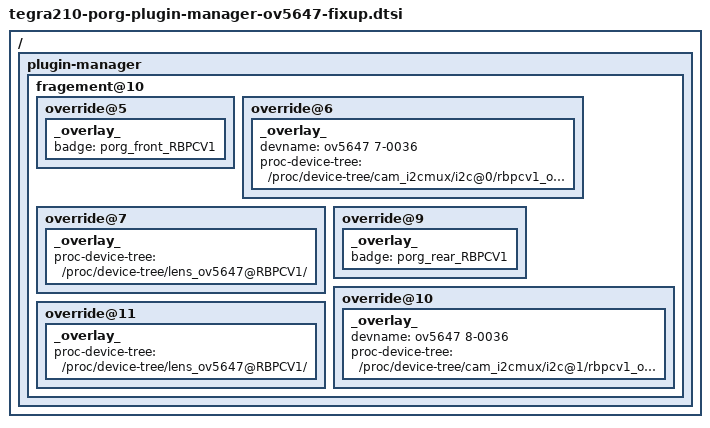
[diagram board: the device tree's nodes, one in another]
/*
 * tegra210-porg-plugin-manager-ov5647-fixup.dtsi
 *
 * The stock porg plugin-manager fragment for B01 modules (ids >= 3448-xxxx-300,
 * "fragement@10" in tegra210-porg-plugin-manager.dtsi) enables the dual camera
 * nodes by label at boot and, in doing so, rewrites the tegra-camera-platform
 * module entries with IMX219 names. Override just those properties so
 * nvargus-daemon looks for the OV5647 v4l2 subdevices instead.
 *
 * This file MUST be included after tegra210-porg-plugin-manager.dtsi
 * (later definitions win in dtc), which is why it is not part of the camera
 * dtsi itself. Node names below match NVIDIA's file exactly, including the
 * "fragement" spelling.
 */

/ {
	plugin-manager {
		fragement@10 {
			override@5 {
				_overlay_ {
					badge = "porg_front_RBPCV1";
				};
			};
			override@6 {
				_overlay_ {
					devname = "ov5647 7-0036";
					proc-device-tree = "/proc/device-tree/cam_i2cmux/i2c@0/rbpcv1_ov5647_a@36";
				};
			};
			override@7 {
				_overlay_ {
					proc-device-tree = "/proc/device-tree/lens_ov5647@RBPCV1/";
				};
			};
			override@9 {
				_overlay_ {
					badge = "porg_rear_RBPCV1";
				};
			};
			override@10 {
				_overlay_ {
					devname = "ov5647 8-0036";
					proc-device-tree = "/proc/device-tree/cam_i2cmux/i2c@1/rbpcv1_ov5647_e@36";
				};
			};
			override@11 {
				_overlay_ {
					proc-device-tree = "/proc/device-tree/lens_ov5647@RBPCV1/";
				};
			};
		};
	};
};
